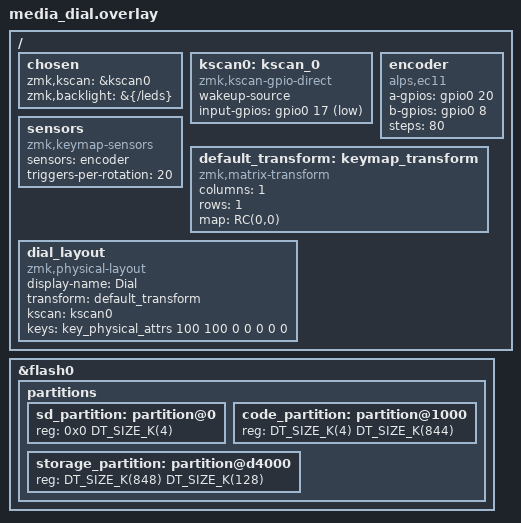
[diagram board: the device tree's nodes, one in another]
/*
 * SPDX-License-Identifier: MIT
 *
 * Encoder SIQ-02FVS3 (3 chan: A - C - B) + 1 nut nhan
 *
 * Day noi tren Pro Micro nRF52840 (build voi board nice_nano_v2):
 *   Encoder chan A  -> P0.20  (chan D3 tren silk)
 *   Encoder chan C  -> GND      (chan giua, chan chung)
 *   Encoder chan B  -> P0.08  (chan D0 tren silk)
 *   Nut nhan        -> P0.17  (chan D2 tren silk)  <-> GND
 *
 * O day ghi thang so GPIO (&gpio0) thay vi so chan pro_micro, vi so GPIO moi
 * la thu quyet dinh. Neu doi sang board khac thi phai doi lai cho khop.
 */

#include <dt-bindings/zmk/matrix_transform.h>
#include <physical_layouts.dtsi>

/*
 * Bootloader tren board nay khong co SoftDevice: no nhay vao ung dung o dia chi
 * 0x1000, trong khi firmware nice_nano_v2 mac dinh nam o 0x26000. Neu khong doi
 * phan vung thi firmware khong bao gio chay, board quay ve che do nap uf2.
 * Doan duoi day chinh la noi dung cua snippet nrf52840-nosd, dat thang vao day
 * de khong bao gio bi quen khi sua build.yaml.
 */
/delete-node/ &sd_partition;
/delete-node/ &code_partition;
/delete-node/ &storage_partition;

&flash0 {
    partitions {
        sd_partition: partition@0 {
            reg = <0x0 DT_SIZE_K(4)>;
        };

        code_partition: partition@1000 {
            reg = <DT_SIZE_K(4) DT_SIZE_K(844)>;
        };

        storage_partition: partition@d4000 {
            reg = <DT_SIZE_K(848) DT_SIZE_K(128)>;
        };
    };
};

/ {
    chosen {
        zmk,kscan = &kscan0;
        // Den xanh san co tren board (P0.15). Muon nhap nhay bao hieu thi phai
        // muon he thong backlight cua ZMK, vi ZMK khong co behavior nao dieu
        // khien den GPIO truc tiep.
        zmk,backlight = &{/leds};
    };

    kscan0: kscan_0 {
        compatible = "zmk,kscan-gpio-direct";
        wakeup-source;

        input-gpios = <&gpio0 17 (GPIO_ACTIVE_LOW | GPIO_PULL_UP)>;
    };

    encoder: encoder {
        compatible = "alps,ec11";
        a-gpios = <&gpio0 20 (GPIO_ACTIVE_HIGH | GPIO_PULL_UP)>;
        b-gpios = <&gpio0 8 (GPIO_ACTIVE_HIGH | GPIO_PULL_UP)>;
        steps = <80>;
        status = "okay";
    };

    sensors: sensors {
        compatible = "zmk,keymap-sensors";
        sensors = <&encoder>;
        triggers-per-rotation = <20>;
    };

    // ZMK Studio bat buoc phai co physical layout kem thuoc tinh "keys",
    // va KHONG duoc dat chosen zmk,matrix-transform.
    default_transform: keymap_transform {
        compatible = "zmk,matrix-transform";
        columns = <1>;
        rows = <1>;
        map = <RC(0,0)>;
    };

    dial_layout: dial_layout {
        compatible = "zmk,physical-layout";
        display-name = "Dial";
        transform = <&default_transform>;
        kscan = <&kscan0>;
        keys  //                     w   h    x    y   rot   rx   ry
            = <&key_physical_attrs 100 100    0    0     0    0    0>
            ;
    };
};
